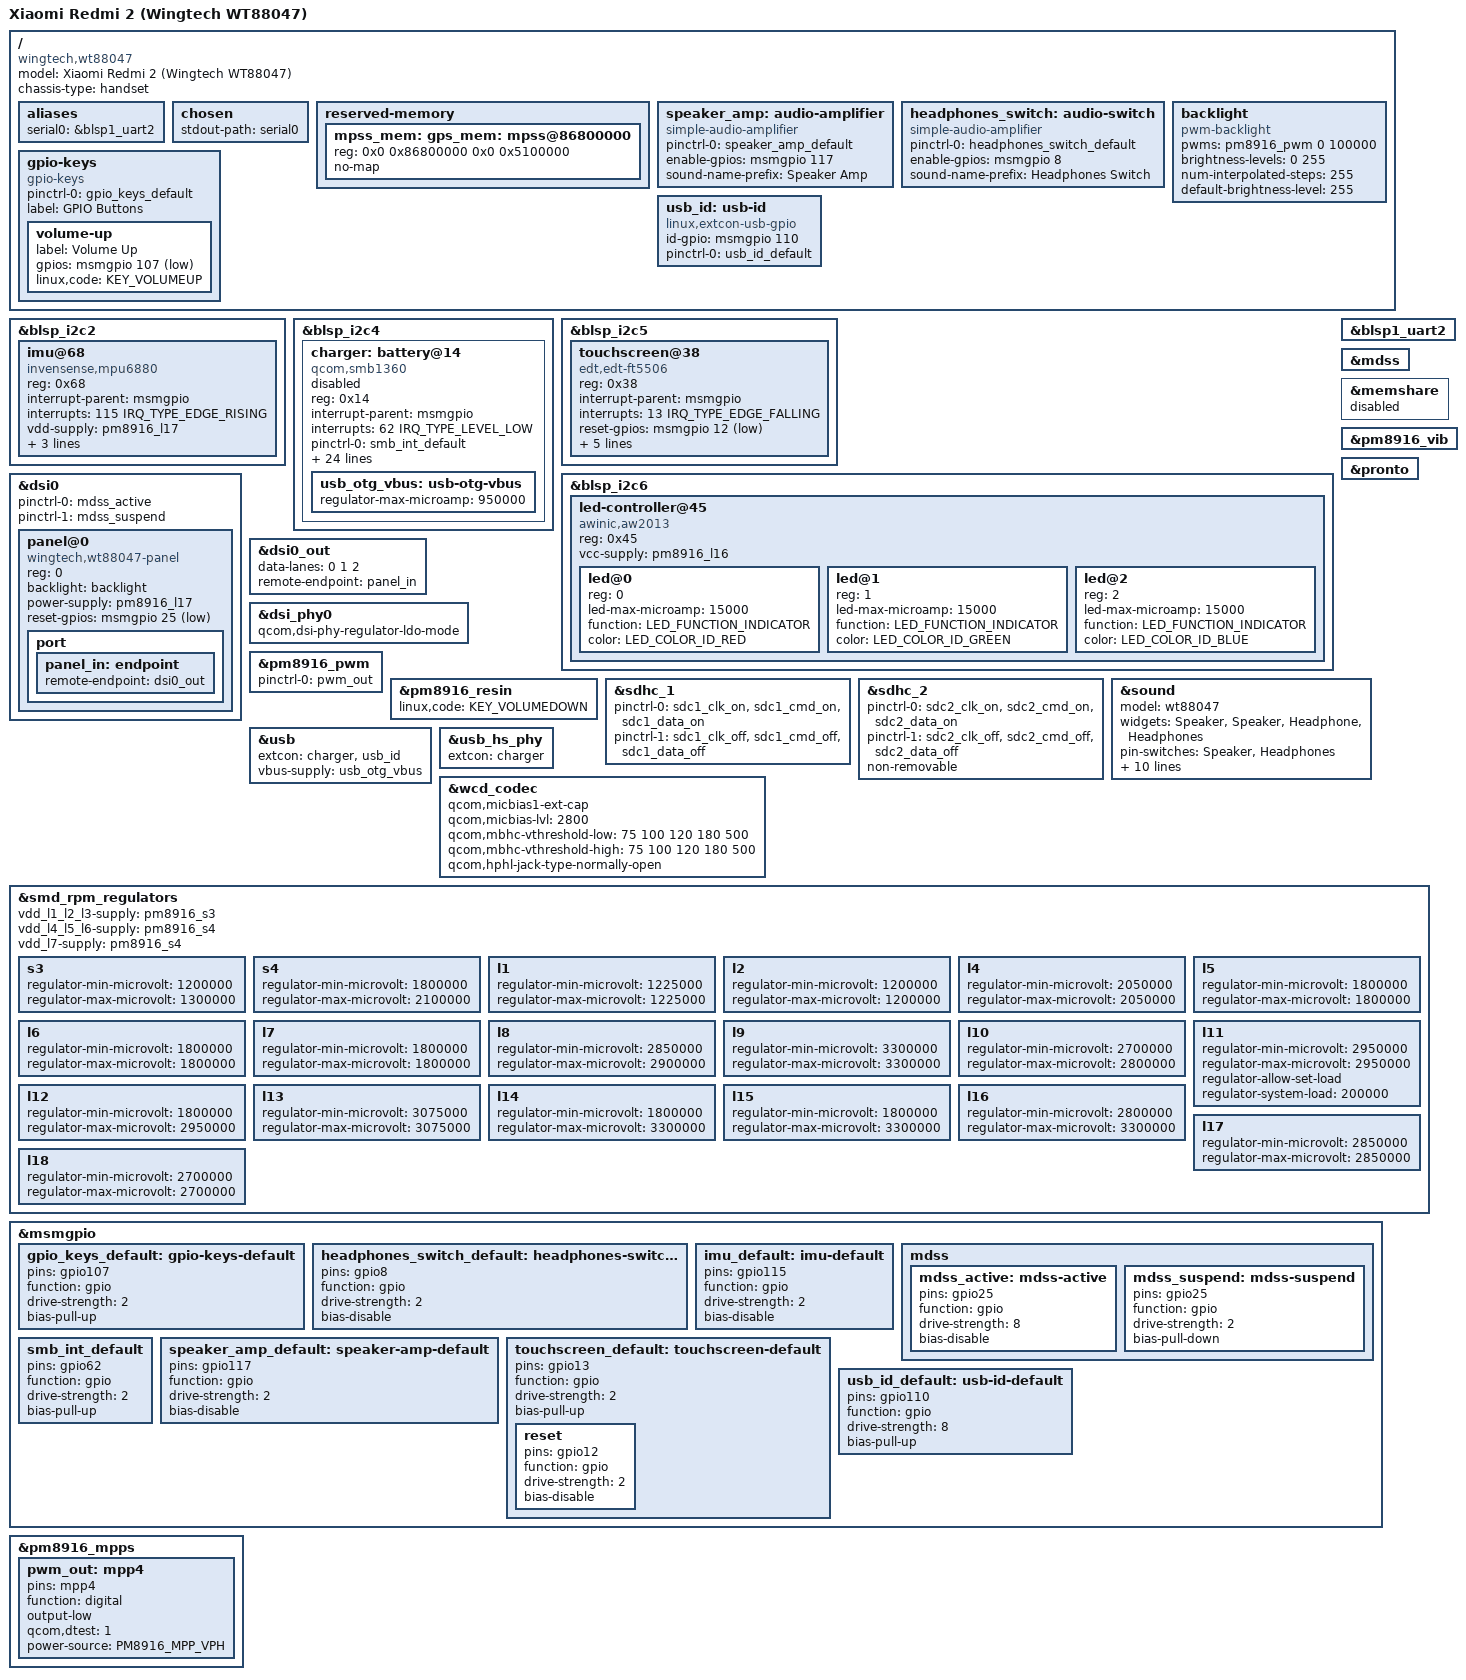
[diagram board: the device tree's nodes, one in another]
// SPDX-License-Identifier: GPL-2.0-only
// Copyright (C) 2020 Stephan Gerhold

/dts-v1/;

#include "msm8916-pm8916.dtsi"
#include "msm8916-modem.dtsi"

#include <dt-bindings/gpio/gpio.h>
#include <dt-bindings/input/input.h>
#include <dt-bindings/leds/common.h>
#include <dt-bindings/pinctrl/qcom,pmic-mpp.h>

/ {
	model = "Xiaomi Redmi 2 (Wingtech WT88047)";
	compatible = "wingtech,wt88047", "qcom,msm8916";
	chassis-type = "handset";

	aliases {
		serial0 = &blsp1_uart2;
	};

	chosen {
		stdout-path = "serial0";
	};

	reserved-memory {
		mpss_mem: gps_mem: mpss@86800000 {
			reg = <0x0 0x86800000 0x0 0x5100000>;
			no-map;
		};
	};

	speaker_amp: audio-amplifier {
		compatible = "simple-audio-amplifier";

		pinctrl-names = "default";
		pinctrl-0 = <&speaker_amp_default>;

		enable-gpios = <&msmgpio 117 GPIO_ACTIVE_HIGH>;
		sound-name-prefix = "Speaker Amp";
	};

	/*
	 * According to the schematics this is actually an analog switch,
	 * but given that we need to enable the GPIO to get sound on headphones,
	 * modelling it as simple-audio-amplifier seems to work just fine.
	 */
	headphones_switch: audio-switch {
		compatible = "simple-audio-amplifier";

		pinctrl-names = "default";
		pinctrl-0 = <&headphones_switch_default>;

		enable-gpios = <&msmgpio 8 GPIO_ACTIVE_HIGH>;
		sound-name-prefix = "Headphones Switch";
	};

	backlight: backlight {
		compatible = "pwm-backlight";
		pwms = <&pm8916_pwm 0 100000>;

		brightness-levels = <0 255>;
		num-interpolated-steps = <255>;
		default-brightness-level = <255>;
	};

	gpio-keys {
		compatible = "gpio-keys";

		pinctrl-names = "default";
		pinctrl-0 = <&gpio_keys_default>;

		label = "GPIO Buttons";

		volume-up {
			label = "Volume Up";
			gpios = <&msmgpio 107 GPIO_ACTIVE_LOW>;
			linux,code = <KEY_VOLUMEUP>;
		};
	};

	usb_id: usb-id {
		compatible = "linux,extcon-usb-gpio";
		id-gpio = <&msmgpio 110 GPIO_ACTIVE_HIGH>;
		pinctrl-names = "default";
		pinctrl-0 = <&usb_id_default>;
	};
};

&blsp_i2c2 {
	status = "okay";

	imu@68 {
		compatible = "invensense,mpu6880";
		reg = <0x68>;

		interrupt-parent = <&msmgpio>;
		interrupts = <115 IRQ_TYPE_EDGE_RISING>;

		vdd-supply = <&pm8916_l17>;
		vddio-supply = <&pm8916_l6>;

		pinctrl-names = "default";
		pinctrl-0 = <&imu_default>;

		mount-matrix = "1",  "0", "0",
			       "0", "-1", "0",
			       "0",  "0", "1";
	};
};

&blsp_i2c4 {
	status = "okay";

	charger: battery@14 {
		compatible = "qcom,smb1360";
		reg = <0x14>;

		interrupt-parent = <&msmgpio>;
		interrupts = <62 IRQ_TYPE_LEVEL_LOW>;

		pinctrl-names = "default";
		pinctrl-0 = <&smb_int_default>;

		/*
		 * Some properties are battery-specific. Battery detection
		 * happens in the bootloader, so it will fill those appropriately
		 * and set status = "okay".
		 */
		status = "disabled";

		qcom,rsense-10mohm;

		qcom,float-voltage-mv = <4350>;
		qcom,iterm-ma = <100>;
		qcom,charging-timeout = <192>; /* Not configured in downstream */
		qcom,chg-inhibit-disabled;

		qcom,fg-batt-capacity-mah = <0>; /* Set by bootloader */
		qcom,fg-cc-soc-coeff = <0>; /* Set by bootloader */
		qcom,fg-cutoff-voltage-mv = <3400>;
		qcom,fg-iterm-ma = <150>;
		qcom,fg-ibatt-standby-ma = <200>;
		qcom,fg-cc-to-cv-mv = <4328>;
		qcom,thermistor-c1-coeff = <0>; /* Set by bootloader */
		qcom,fg-auto-recharge-soc = <95>; /* 99 in downstream */

		qcom,otp-hard-jeita-config;
		qcom,otp-hot-bat-decidegc = <600>;
		qcom,otp-cold-bat-decidegc = <0>;

		qcom,soft-jeita-config;
		qcom,warm-bat-decidegc = <450>;
		qcom,cool-bat-decidegc = <100>;
		qcom,soft-jeita-comp-voltage-mv = <4000>;
		qcom,soft-jeita-comp-current-ma = <600>;

		qcom,shdn-after-pwroff;
		qcom,fg-reset-at-pon;
		qcom,fg-reset-threshold-mv = <100>;

		usb_otg_vbus: usb-otg-vbus {
			regulator-max-microamp = <950000>;
		};
	};
};

&blsp_i2c5 {
	status = "okay";

	touchscreen@38 {
		/* Likely some other model but works just fine with this one */
		compatible = "edt,edt-ft5506";
		reg = <0x38>;

		interrupt-parent = <&msmgpio>;
		interrupts = <13 IRQ_TYPE_EDGE_FALLING>;

		reset-gpios = <&msmgpio 12 GPIO_ACTIVE_LOW>;

		vcc-supply = <&pm8916_l17>;
		iovcc-supply = <&pm8916_l6>;

		touchscreen-size-x = <720>;
		touchscreen-size-y = <1280>;

		pinctrl-names = "default";
		pinctrl-0 = <&touchscreen_default>;
	};
};

&blsp_i2c6 {
	status = "okay";

	led-controller@45 {
		compatible = "awinic,aw2013";
		reg = <0x45>;
		#address-cells = <1>;
		#size-cells = <0>;

		vcc-supply = <&pm8916_l16>;

		led@0 {
			reg = <0>;
			led-max-microamp = <15000>;
			function = LED_FUNCTION_INDICATOR;
			color = <LED_COLOR_ID_RED>;
		};

		led@1 {
			reg = <1>;
			led-max-microamp = <15000>;
			function = LED_FUNCTION_INDICATOR;
			color = <LED_COLOR_ID_GREEN>;
		};

		led@2 {
			reg = <2>;
			led-max-microamp = <15000>;
			function = LED_FUNCTION_INDICATOR;
			color = <LED_COLOR_ID_BLUE>;
		};
	};
};

&blsp1_uart2 {
	status = "okay";
};

&dsi0 {
	pinctrl-names = "default", "sleep";
	pinctrl-0 = <&mdss_active>;
	pinctrl-1 = <&mdss_suspend>;

	panel@0 {
		compatible = "wingtech,wt88047-panel";
		reg = <0>;

		backlight = <&backlight>;
		power-supply = <&pm8916_l17>;
		reset-gpios = <&msmgpio 25 GPIO_ACTIVE_LOW>;

		port {
			panel_in: endpoint {
				remote-endpoint = <&dsi0_out>;
			};
		};
	};
};

&dsi0_out {
	data-lanes = <0 1 2>;
	remote-endpoint = <&panel_in>;
};

&dsi_phy0 {
	qcom,dsi-phy-regulator-ldo-mode;
};

&mdss {
	status = "okay";
};

/*
 * The modem firmware sends a "query_size" memshare request for client ID 1,
 * but basically does not do anything with it. GPS works only if:
 *   - Memshare is not present or
 *   - Memshare replies to the request with an error
 * Overall it seems pointless to enable memshare for this device.
 */
&memshare {
	status = "disabled";
};

&pm8916_pwm {
	status = "okay";
	pinctrl-names = "default";
	pinctrl-0 = <&pwm_out>;
};

&pm8916_resin {
	status = "okay";
	linux,code = <KEY_VOLUMEDOWN>;
};

&pm8916_vib {
	status = "okay";
};

&pronto {
	status = "okay";
};

&sdhc_1 {
	status = "okay";

	pinctrl-names = "default", "sleep";
	pinctrl-0 = <&sdc1_clk_on &sdc1_cmd_on &sdc1_data_on>;
	pinctrl-1 = <&sdc1_clk_off &sdc1_cmd_off &sdc1_data_off>;
};

&sdhc_2 {
	status = "okay";

	pinctrl-names = "default", "sleep";
	pinctrl-0 = <&sdc2_clk_on &sdc2_cmd_on &sdc2_data_on>;
	pinctrl-1 = <&sdc2_clk_off &sdc2_cmd_off &sdc2_data_off>;

	non-removable;
};

&sound {
	status = "okay";

	model = "wt88047";
	widgets =
		"Speaker", "Speaker",
		"Headphone", "Headphones";
	pin-switches = "Speaker", "Headphones";
	audio-routing =
		"Speaker", "Speaker Amp OUTL",
		"Speaker", "Speaker Amp OUTR",
		"Speaker Amp INL", "HPH_R",
		"Speaker Amp INR", "HPH_R",
		"Headphones", "Headphones Switch OUTL",
		"Headphones", "Headphones Switch OUTR",
		"Headphones Switch INL", "HPH_L",
		"Headphones Switch INR", "HPH_R",
		"AMIC1", "MIC BIAS External1",
		"AMIC2", "MIC BIAS Internal2";
	aux-devs = <&speaker_amp>, <&headphones_switch>;
};

&usb {
	status = "okay";
	extcon = <&charger>, <&usb_id>;
	vbus-supply = <&usb_otg_vbus>;
};

&usb_hs_phy {
	extcon = <&charger>;
};

&wcd_codec {
	qcom,micbias1-ext-cap;
	qcom,micbias-lvl = <2800>;
	qcom,mbhc-vthreshold-low = <75 100 120 180 500>;
	qcom,mbhc-vthreshold-high = <75 100 120 180 500>;
	qcom,hphl-jack-type-normally-open;
};

&smd_rpm_regulators {
	vdd_l1_l2_l3-supply = <&pm8916_s3>;
	vdd_l4_l5_l6-supply = <&pm8916_s4>;
	vdd_l7-supply = <&pm8916_s4>;

	s3 {
		regulator-min-microvolt = <1200000>;
		regulator-max-microvolt = <1300000>;
	};

	s4 {
		regulator-min-microvolt = <1800000>;
		regulator-max-microvolt = <2100000>;
	};

	l1 {
		regulator-min-microvolt = <1225000>;
		regulator-max-microvolt = <1225000>;
	};

	l2 {
		regulator-min-microvolt = <1200000>;
		regulator-max-microvolt = <1200000>;
	};

	l4 {
		regulator-min-microvolt = <2050000>;
		regulator-max-microvolt = <2050000>;
	};

	l5 {
		regulator-min-microvolt = <1800000>;
		regulator-max-microvolt = <1800000>;
	};

	l6 {
		regulator-min-microvolt = <1800000>;
		regulator-max-microvolt = <1800000>;
	};

	l7 {
		regulator-min-microvolt = <1800000>;
		regulator-max-microvolt = <1800000>;
	};

	l8 {
		regulator-min-microvolt = <2850000>;
		regulator-max-microvolt = <2900000>;
	};

	l9 {
		regulator-min-microvolt = <3300000>;
		regulator-max-microvolt = <3300000>;
	};

	l10 {
		regulator-min-microvolt = <2700000>;
		regulator-max-microvolt = <2800000>;
	};

	l11 {
		regulator-min-microvolt = <2950000>;
		regulator-max-microvolt = <2950000>;
		regulator-allow-set-load;
		regulator-system-load = <200000>;
	};

	l12 {
		regulator-min-microvolt = <1800000>;
		regulator-max-microvolt = <2950000>;
	};

	l13 {
		regulator-min-microvolt = <3075000>;
		regulator-max-microvolt = <3075000>;
	};

	l14 {
		regulator-min-microvolt = <1800000>;
		regulator-max-microvolt = <3300000>;
	};

	l15 {
		regulator-min-microvolt = <1800000>;
		regulator-max-microvolt = <3300000>;
	};

	l16 {
		regulator-min-microvolt = <2800000>;
		regulator-max-microvolt = <3300000>;
	};

	l17 {
		regulator-min-microvolt = <2850000>;
		regulator-max-microvolt = <2850000>;
	};

	l18 {
		regulator-min-microvolt = <2700000>;
		regulator-max-microvolt = <2700000>;
	};
};

&msmgpio {
	gpio_keys_default: gpio-keys-default {
		pins = "gpio107";
		function = "gpio";

		drive-strength = <2>;
		bias-pull-up;
	};

	headphones_switch_default: headphones-switch-default {
		pins = "gpio8";
		function = "gpio";

		drive-strength = <2>;
		bias-disable;
	};

	imu_default: imu-default {
		pins = "gpio115";
		function = "gpio";

		drive-strength = <2>;
		bias-disable;
	};

	mdss {
		mdss_active: mdss-active {
			pins = "gpio25";
			function = "gpio";

			drive-strength = <8>;
			bias-disable;
		};
		mdss_suspend: mdss-suspend {
			pins = "gpio25";
			function = "gpio";

			drive-strength = <2>;
			bias-pull-down;
		};
	};

	smb_int_default: smb_int_default {
		pins = "gpio62";
		function = "gpio";

		drive-strength = <2>;
		bias-pull-up;
	};

	speaker_amp_default: speaker-amp-default {
		pins = "gpio117";
		function = "gpio";

		drive-strength = <2>;
		bias-disable;
	};

	touchscreen_default: touchscreen-default {
		pins = "gpio13";
		function = "gpio";

		drive-strength = <2>;
		bias-pull-up;

		reset {
			pins = "gpio12";
			function = "gpio";

			drive-strength = <2>;
			bias-disable;
		};
	};

	usb_id_default: usb-id-default {
		pins = "gpio110";
		function = "gpio";

		drive-strength = <8>;
		bias-pull-up;
	};
};

&pm8916_mpps {
	pwm_out: mpp4 {
		pins = "mpp4";
		function = "digital";

		output-low;
		qcom,dtest = <1>;
		power-source = <PM8916_MPP_VPH>;
	};
};
